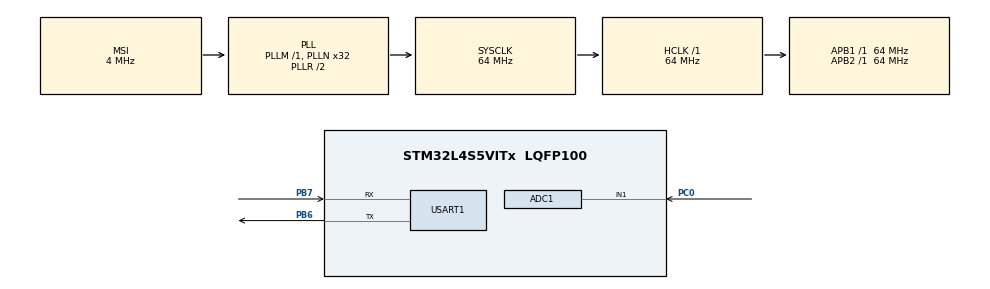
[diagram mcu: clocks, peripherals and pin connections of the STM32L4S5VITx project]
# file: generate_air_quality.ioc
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ADC1.Channel-0\#ChannelRegularConversion=ADC_CHANNEL_1
ADC1.ClockPrescaler=ADC_CLOCK_ASYNC_DIV4
ADC1.NbrOfConversionFlag=1
ADC1.OffsetNumber-0\#ChannelRegularConversion=ADC_OFFSET_NONE
ADC1.Rank-0\#ChannelRegularConversion=1
ADC1.SamplingTime-0\#ChannelRegularConversion=ADC_SAMPLETIME_2CYCLES_5
ADC1.master=1
Mcu.Family=STM32L4
Mcu.Name=STM32L4S5VITx
Mcu.Package=LQFP100
NVIC.PriorityGroup=NVIC_PRIORITYGROUP_4
PB6.Mode=Asynchronous
PB6.Signal=USART1_TX
PB7.Mode=Asynchronous
PB7.Signal=USART1_RX
PC0.Signal=ADCx_IN1
ProjectManager.HeapSize=0x200
ProjectManager.StackSize=0x400
ProjectManager.TargetToolchain=STM32CubeIDE
RCC.ADCFreq_Value=32000000
RCC.AHBFreq_Value=64000000
RCC.APB1Freq_Value=64000000
RCC.APB1TimFreq_Value=64000000
RCC.APB2Freq_Value=64000000
RCC.APB2TimFreq_Value=64000000
RCC.CortexFreq_Value=64000000
RCC.HCLKFreq_Value=64000000
RCC.HSE_VALUE=8000000
RCC.HSI48_VALUE=48000000
RCC.HSI_VALUE=16000000
RCC.LSE_VALUE=32768
RCC.MSI_VALUE=4000000
RCC.PLLN=32
RCC.PLLSAI1N=16
RCC.SYSCLKFreq_VALUE=64000000
RCC.SYSCLKSource=RCC_SYSCLKSOURCE_PLLCLK
RCC.USBFreq_Value=32000000
RCC.VCOOutputFreq_Value=128000000
SH.ADCx_IN1.0=ADC1_IN1,IN1-Single-Ended
USART1.VirtualMode-Asynchronous=VM_ASYNC
board=B-L4S5I-IOT01A

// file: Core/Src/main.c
/* USER CODE BEGIN Header */
/**
  ******************************************************************************
  * @file           : main.c
  * @brief          : Main program body
  ******************************************************************************
  * @attention
  *
  * Copyright (c) 2024 STMicroelectronics.
  * All rights reserved.
  *
  * This software is licensed under terms that can be found in the LICENSE file
  * in the root directory of this software component.
  * If no LICENSE file comes with this software, it is provided AS-IS.
  *
  ******************************************************************************
  */
/* USER CODE END Header */
#include "main.h"

/* USER CODE BEGIN Includes */
#include "Air_Quality_Sensor.h"
#include <stdio.h>
/* USER CODE END Includes */

ADC_HandleTypeDef hadc1;

UART_HandleTypeDef huart1;

/* USER CODE BEGIN PV */
int air_quality_pin;
int lastVoltage = 0;
int currentVoltage = 0;
int standardVoltage = 0;
long voltageSum = 0;
int volSumCount = 0;
long lastStdVolUpdated = 0;
/* USER CODE END PV */

void SystemClock_Config(void);
static void MX_GPIO_Init(void);
static void MX_ADC1_Init(void);
static void MX_USART1_UART_Init(void);

int main(void)
{

  /* USER CODE BEGIN 1 */
	void AirQualitySensor_Init(void) {
	    HAL_ADC_Start(&hadc1);
	    HAL_ADC_PollForConversion(&hadc1, HAL_MAX_DELAY);
	    int initVoltage = HAL_ADC_GetValue(&hadc1);

	    if (initVoltage > 10 && initVoltage < 798) {
	        currentVoltage = initVoltage;
	        lastVoltage = currentVoltage;

	        standardVoltage = initVoltage;
	        lastStdVolUpdated = HAL_GetTick();
	    }
	}

int AirQualitySensor_ReadValue(void) {
    HAL_ADC_Start(&hadc1);
    HAL_ADC_PollForConversion(&hadc1, HAL_MAX_DELAY);
    currentVoltage = HAL_ADC_GetValue(&hadc1);

       // Print the current ADC value
        //char buffer[50];
        //printf("Air Quality Sensor ADC Value: %d\r\n", currentVoltage);
        //UART_Print(buffer);

    return currentVoltage;
}

int AirQualitySensor_CalculateSlope(void) {
    return (currentVoltage - lastVoltage);
}

void AirQualitySensor_UpdateStandardVoltage(void) {
    if (HAL_GetTick() - lastStdVolUpdated > 60000) {  // Update every 60 seconds
        standardVoltage = voltageSum / volSumCount;
        voltageSum = 0;
        volSumCount = 0;
        lastStdVolUpdated = HAL_GetTick();
    }
}

void AirQualitySensor_PrintLevel(int adcValue) {

    if (adcValue < 200) {  // Example threshold for Low Pollution
        printf("Air Quality Level: Low Pollution\r\n");
    } else if (adcValue < 400) {  // Example threshold for Medium Pollution
        printf("Air Quality Level: Medium Pollution\r\n");
    } else if (adcValue < 600) {  // Example threshold for High Pollution
        printf("Air Quality Level: High Pollution\r\n");
    } else {
        printf("Air Quality Level: Fresh Air\r\n");
    }

    //UART_Print(buffer);  // Send the classification to the serial console
}
  /* USER CODE END 1 */

  /* MCU Configuration--------------------------------------------------------*/

  /* Reset of all peripherals, Initializes the Flash interface and the Systick. */
  HAL_Init();

  /* Configure the system clock */
  SystemClock_Config();

  /* Initialize all configured peripherals */
  MX_GPIO_Init();
  MX_ADC1_Init();
  MX_USART1_UART_Init();
  /* USER CODE BEGIN 2 */
  AirQualitySensor_Init();
  /* USER CODE END 2 */

  /* Infinite loop */
  /* USER CODE BEGIN WHILE */
  while (1)
  {
      AirQualitySensor_ReadValue();
      AirQualitySensor_PrintLevel(currentVoltage);
      HAL_Delay(200);
    /* USER CODE END WHILE */

  }
}

void SystemClock_Config(void)
{
  RCC_OscInitTypeDef RCC_OscInitStruct = {0};
  RCC_ClkInitTypeDef RCC_ClkInitStruct = {0};

  /** Configure the main internal regulator output voltage
  */
  if (HAL_PWREx_ControlVoltageScaling(PWR_REGULATOR_VOLTAGE_SCALE1) != HAL_OK)
  {
    Error_Handler();
  }

  /** Initializes the RCC Oscillators according to the specified parameters
  * in the RCC_OscInitTypeDef structure.
  */
  RCC_OscInitStruct.OscillatorType = RCC_OSCILLATORTYPE_MSI;
  RCC_OscInitStruct.MSIState = RCC_MSI_ON;
  RCC_OscInitStruct.MSICalibrationValue = 0;
  RCC_OscInitStruct.MSIClockRange = RCC_MSIRANGE_6;
  RCC_OscInitStruct.PLL.PLLState = RCC_PLL_ON;
  RCC_OscInitStruct.PLL.PLLSource = RCC_PLLSOURCE_MSI;
  RCC_OscInitStruct.PLL.PLLM = 1;
  RCC_OscInitStruct.PLL.PLLN = 32;
  RCC_OscInitStruct.PLL.PLLP = RCC_PLLP_DIV2;
  RCC_OscInitStruct.PLL.PLLQ = RCC_PLLQ_DIV2;
  RCC_OscInitStruct.PLL.PLLR = RCC_PLLR_DIV2;
  if (HAL_RCC_OscConfig(&RCC_OscInitStruct) != HAL_OK)
  {
    Error_Handler();
  }

  /** Initializes the CPU, AHB and APB buses clocks
  */
  RCC_ClkInitStruct.ClockType = RCC_CLOCKTYPE_HCLK|RCC_CLOCKTYPE_SYSCLK
                              |RCC_CLOCKTYPE_PCLK1|RCC_CLOCKTYPE_PCLK2;
  RCC_ClkInitStruct.SYSCLKSource = RCC_SYSCLKSOURCE_PLLCLK;
  RCC_ClkInitStruct.AHBCLKDivider = RCC_SYSCLK_DIV1;
  RCC_ClkInitStruct.APB1CLKDivider = RCC_HCLK_DIV1;
  RCC_ClkInitStruct.APB2CLKDivider = RCC_HCLK_DIV1;

  if (HAL_RCC_ClockConfig(&RCC_ClkInitStruct, FLASH_LATENCY_3) != HAL_OK)
  {
    Error_Handler();
  }
}

static void MX_ADC1_Init(void)
{

  ADC_ChannelConfTypeDef sConfig = {0};

  /** Common config
  */
  hadc1.Instance = ADC1;
  hadc1.Init.ClockPrescaler = ADC_CLOCK_ASYNC_DIV4;
  hadc1.Init.Resolution = ADC_RESOLUTION_12B;
  hadc1.Init.DataAlign = ADC_DATAALIGN_RIGHT;
  hadc1.Init.ScanConvMode = ADC_SCAN_DISABLE;
  hadc1.Init.EOCSelection = ADC_EOC_SINGLE_CONV;
  hadc1.Init.LowPowerAutoWait = DISABLE;
  hadc1.Init.ContinuousConvMode = DISABLE;
  hadc1.Init.NbrOfConversion = 1;
  hadc1.Init.DiscontinuousConvMode = DISABLE;
  hadc1.Init.ExternalTrigConv = ADC_SOFTWARE_START;
  hadc1.Init.ExternalTrigConvEdge = ADC_EXTERNALTRIGCONVEDGE_NONE;
  hadc1.Init.DMAContinuousRequests = DISABLE;
  hadc1.Init.Overrun = ADC_OVR_DATA_PRESERVED;
  hadc1.Init.OversamplingMode = DISABLE;
  if (HAL_ADC_Init(&hadc1) != HAL_OK)
  {
    Error_Handler();
  }

  /** Configure Regular Channel
  */
  sConfig.Channel = ADC_CHANNEL_1;
  sConfig.Rank = ADC_REGULAR_RANK_1;
  sConfig.SamplingTime = ADC_SAMPLETIME_2CYCLES_5;
  sConfig.SingleDiff = ADC_SINGLE_ENDED;
  sConfig.OffsetNumber = ADC_OFFSET_NONE;
  sConfig.Offset = 0;
  if (HAL_ADC_ConfigChannel(&hadc1, &sConfig) != HAL_OK)
  {
    Error_Handler();
  }

}

static void MX_USART1_UART_Init(void)
{

  huart1.Instance = USART1;
  huart1.Init.BaudRate = 115200;
  huart1.Init.WordLength = UART_WORDLENGTH_8B;
  huart1.Init.StopBits = UART_STOPBITS_1;
  huart1.Init.Parity = UART_PARITY_NONE;
  huart1.Init.Mode = UART_MODE_TX_RX;
  huart1.Init.HwFlowCtl = UART_HWCONTROL_NONE;
  huart1.Init.OverSampling = UART_OVERSAMPLING_16;
  huart1.Init.OneBitSampling = UART_ONE_BIT_SAMPLE_DISABLE;
  huart1.Init.ClockPrescaler = UART_PRESCALER_DIV1;
  huart1.AdvancedInit.AdvFeatureInit = UART_ADVFEATURE_NO_INIT;
  if (HAL_UART_Init(&huart1) != HAL_OK)
  {
    Error_Handler();
  }
  if (HAL_UARTEx_SetTxFifoThreshold(&huart1, UART_TXFIFO_THRESHOLD_1_8) != HAL_OK)
  {
    Error_Handler();
  }
  if (HAL_UARTEx_SetRxFifoThreshold(&huart1, UART_RXFIFO_THRESHOLD_1_8) != HAL_OK)
  {
    Error_Handler();
  }
  if (HAL_UARTEx_DisableFifoMode(&huart1) != HAL_OK)
  {
    Error_Handler();
  }

}

static void MX_GPIO_Init(void)
{

  /* GPIO Ports Clock Enable */
  __HAL_RCC_GPIOC_CLK_ENABLE();
  __HAL_RCC_GPIOB_CLK_ENABLE();

}

/* USER CODE BEGIN 4 */
int __io_putchar(int ch)
{
	HAL_UART_Transmit(&huart1, (uint8_t *)&ch, 1, HAL_MAX_DELAY);
	return ch;
}
/* USER CODE END 4 */

void Error_Handler(void)
{
  __disable_irq();
  while (1)
  {
  }
}
